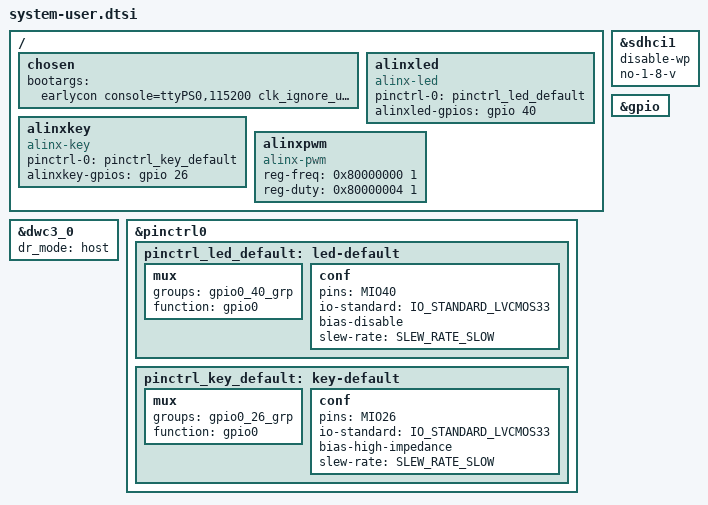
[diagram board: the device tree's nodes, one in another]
#include <dt-bindings/pinctrl/pinctrl-zynqmp.h>

/include/ "system-conf.dtsi"
/ {
    chosen {
    	bootargs = "earlycon console=ttyPS0,115200 clk_ignore_unused root=/dev/mmcblk1p2 rw rootwait cma=512M";
    };
};

/* SD */
&sdhci1 {
	disable-wp;
	no-1-8-v;
};

/* USB */
&dwc3_0 {
	status = "okay";
	dr_mode = "host";
};

&gpio {
    status = "okay";
};

&pinctrl0 { 
    status = "okay";
        
    pinctrl_led_default: led-default { 
        mux { 
            groups = "gpio0_40_grp";
            function = "gpio0"; 
        };
            
        conf { 
            pins = "MIO40";
            io-standard = <IO_STANDARD_LVCMOS33>; 
            bias-disable;
            slew-rate = <SLEW_RATE_SLOW>;
        };
    }; 
    
    pinctrl_key_default: key-default {
        mux {
            groups = "gpio0_26_grp";
            function = "gpio0";
        };

        conf {
            pins = "MIO26";
            io-standard = <IO_STANDARD_LVCMOS33>;
            bias-high-impedance;
            slew-rate = <SLEW_RATE_SLOW>;
        };
    };
};

/ {
    alinxled {
        compatible = "alinx-led";
        pinctrl-names = "default";
        pinctrl-0 = <&pinctrl_led_default>;
        alinxled-gpios = <&gpio 40 0>;
    };
    
    alinxkey {
        compatible = "alinx-key";
        pinctrl-names = "default";
        pinctrl-0 = <&pinctrl_key_default>;
        alinxkey-gpios = <&gpio 26 0>;
    };
    
    alinxpwm {  
        compatible = "alinx-pwm";  
        reg-freq = <0x80000000 1>;  
        reg-duty = <0x80000004 1>;  
    };
    
};


